AUTOSAR XML (schema 4-0-3)
standard types defined: Boolean, UInt16, UInt32
package /AUTOSAR_Platform/DataConstrs
  range DC_Boolean: raw 0..1
  range DC_UInt16: raw 0..65535
package /PATAC/MSM/ComponentTypes
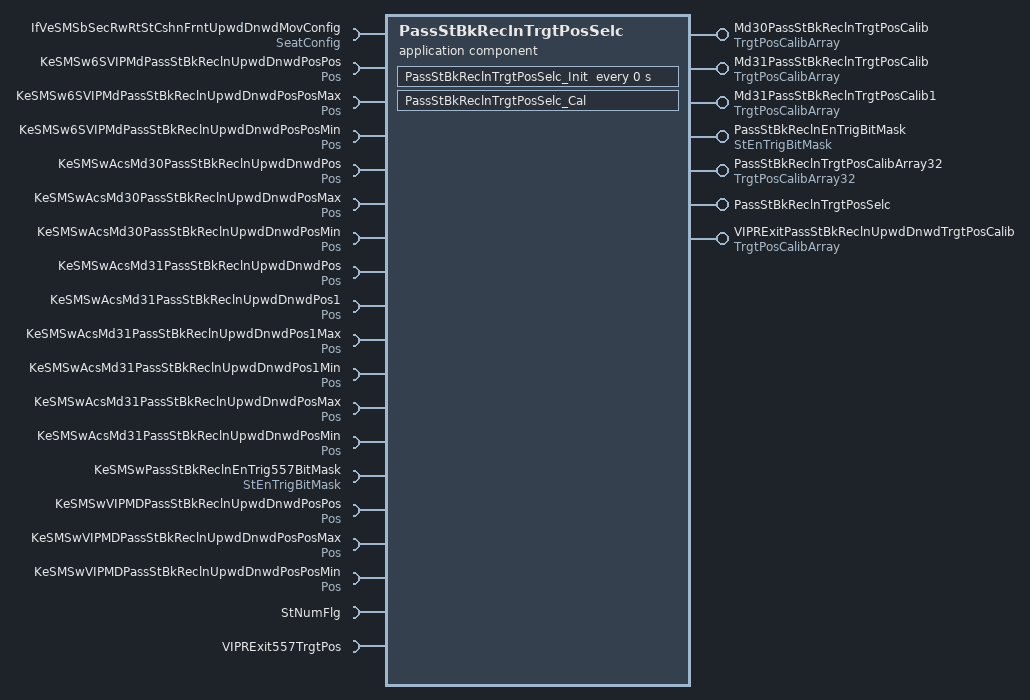
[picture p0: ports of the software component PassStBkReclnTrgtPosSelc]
  application sw component type PassStBkReclnTrgtPosSelc
    7 x provide port:
      Md30PassStBkReclnTrgtPosCalib: nonqueued-sender-com-spec{data-element=TrgtPosArray, init-value=[4095, 4095, 4095]}, provided-interface=TrgtPosCalibArray
      Md31PassStBkReclnTrgtPosCalib: nonqueued-sender-com-spec{data-element=TrgtPosArray, init-value=[4095, 4095, 4095]}, provided-interface=TrgtPosCalibArray
      Md31PassStBkReclnTrgtPosCalib1: nonqueued-sender-com-spec{data-element=TrgtPosArray, init-value=[4095, 4095, 4095]}, provided-interface=TrgtPosCalibArray
      PassStBkReclnEnTrigBitMask: nonqueued-sender-com-spec=data-element=StEnTrigBitMask/Val, provided-interface=StEnTrigBitMask
      PassStBkReclnTrgtPosCalibArray32: nonqueued-sender-com-spec{data-element=TrgtPosArray32, init-value=96 x 4095}, provided-interface=TrgtPosCalibArray32
      PassStBkReclnTrgtPosSelc: server-com-spec{operation=Cal, queue-length=1}, provided-interface=PassStBkReclnTrgtPosSelc
      VIPRExitPassStBkReclnUpwdDnwdTrgtPosCalib: nonqueued-sender-com-spec{data-element=TrgtPosArray, init-value=[4095, 4095, 4095]}, provided-interface=TrgtPosCalibArray
    19 x require port:
      IfVeSMSbSecRwRtStCshnFrntUpwdDnwdMovConfig: nonqueued-receiver-com-spec{data-element=SeatConfig/Val, filter=data-filter-type=ALWAYS, init-value=0}, required-interface=SeatConfig
      KeSMSw6SVIPMdPassStBkReclnUpwdDnwdPosPos: parameter-require-com-spec{init-value=0, parameter=Pos/Val}, required-interface=Pos
      KeSMSw6SVIPMdPassStBkReclnUpwdDnwdPosPosMax: parameter-require-com-spec{init-value=0, parameter=Pos/Val}, required-interface=Pos
      KeSMSw6SVIPMdPassStBkReclnUpwdDnwdPosPosMin: parameter-require-com-spec{init-value=0, parameter=Pos/Val}, required-interface=Pos
      KeSMSwAcsMd30PassStBkReclnUpwdDnwdPos: parameter-require-com-spec{init-value=0, parameter=Pos/Val}, required-interface=Pos
      KeSMSwAcsMd30PassStBkReclnUpwdDnwdPosMax: parameter-require-com-spec{init-value=0, parameter=Pos/Val}, required-interface=Pos
      KeSMSwAcsMd30PassStBkReclnUpwdDnwdPosMin: parameter-require-com-spec{init-value=0, parameter=Pos/Val}, required-interface=Pos
      KeSMSwAcsMd31PassStBkReclnUpwdDnwdPos: parameter-require-com-spec{init-value=0, parameter=Pos/Val}, required-interface=Pos
      KeSMSwAcsMd31PassStBkReclnUpwdDnwdPos1: parameter-require-com-spec{init-value=0, parameter=Pos/Val}, required-interface=Pos
      KeSMSwAcsMd31PassStBkReclnUpwdDnwdPos1Max: parameter-require-com-spec{init-value=0, parameter=Pos/Val}, required-interface=Pos
      KeSMSwAcsMd31PassStBkReclnUpwdDnwdPos1Min: parameter-require-com-spec{init-value=0, parameter=Pos/Val}, required-interface=Pos
      KeSMSwAcsMd31PassStBkReclnUpwdDnwdPosMax: parameter-require-com-spec{init-value=0, parameter=Pos/Val}, required-interface=Pos
      KeSMSwAcsMd31PassStBkReclnUpwdDnwdPosMin: parameter-require-com-spec{init-value=0, parameter=Pos/Val}, required-interface=Pos
      KeSMSwPassStBkReclnEnTrig557BitMask: parameter-require-com-spec{init-value=6153, parameter=StEnTrigBitMask/Val}, required-interface=StEnTrigBitMask
      KeSMSwVIPMDPassStBkReclnUpwdDnwdPosPos: parameter-require-com-spec{init-value=0, parameter=Pos/Val}, required-interface=Pos
      KeSMSwVIPMDPassStBkReclnUpwdDnwdPosPosMax: parameter-require-com-spec{init-value=0, parameter=Pos/Val}, required-interface=Pos
      KeSMSwVIPMDPassStBkReclnUpwdDnwdPosPosMin: parameter-require-com-spec{init-value=0, parameter=Pos/Val}, required-interface=Pos
      StNumFlg: required-interface=StNumFlg
        required-com-specs:
          data-element=Is4s, filter=data-filter-type=ALWAYS, init-value=0
          data-element=Is6s, filter=data-filter-type=ALWAYS, init-value=0
          data-element=Is6s7s, filter=data-filter-type=ALWAYS, init-value=0
          data-element=Is7s, filter=data-filter-type=ALWAYS, init-value=0
      VIPRExit557TrgtPos: required-com-specs=[Get, Set], required-interface=VIPRExit557TrgtPos
    behavior PassStBkReclnTrgtPosSelc_InternalBehavior
      operation invoked event OIT_PassStBkReclnTrgtPosSelc_Cal_PassStBkReclnTrgtPosSelc_Cal: start-on-event=PassStBkReclnTrgtPosSelc_Cal, operation=PassStBkReclnTrgtPosSelc.Cal
      timing event PassStBkReclnTrgtPosSelc_InitEvent: start-on-event=PassStBkReclnTrgtPosSelc_Init, period=0
      runnable PassStBkReclnTrgtPosSelc_Cal
        data-receive-point-by-arguments:
          5 x access:
            REC_IfVeSMSbSecRwRtStCshnFrntUpwdDnwdMovConfig_Val: accessed-variable=IfVeSMSbSecRwRtStCshnFrntUpwdDnwdMovConfig.Val
            REC_StNumFlg_Is4s: accessed-variable=StNumFlg.Is4s
            REC_StNumFlg_Is6s: accessed-variable=StNumFlg.Is6s
            REC_StNumFlg_Is6s7s: accessed-variable=StNumFlg.Is6s7s
            REC_StNumFlg_Is7s: accessed-variable=StNumFlg.Is7s
        data-send-points:
          6 x access:
            SEND_Md30PassStBkReclnTrgtPosCalib_TrgtPosArray: accessed-variable=Md30PassStBkReclnTrgtPosCalib.TrgtPosArray
            SEND_Md31PassStBkReclnTrgtPosCalib_TrgtPosArray: accessed-variable=Md31PassStBkReclnTrgtPosCalib.TrgtPosArray
            SEND_Md31PassStBkReclnTrgtPosCalib1_TrgtPosArray: accessed-variable=Md31PassStBkReclnTrgtPosCalib1.TrgtPosArray
            SEND_PassStBkReclnEnTrigBitMask_Val: accessed-variable=PassStBkReclnEnTrigBitMask.Val
            SEND_PassStBkReclnTrgtPosCalibArray32_TrgtPosArray32: accessed-variable=PassStBkReclnTrgtPosCalibArray32.TrgtPosArray32
            SEND_VIPRExitPassStBkReclnUpwdDnwdTrgtPosCalib_TrgtPosArray: accessed-variable=VIPRExitPassStBkReclnUpwdDnwdTrgtPosCalib.TrgtPosArray
        16 x parameter access:
          PA_KeSMSw6SVIPMdPassStBkReclnUpwdDnwdPosPos_Val: accessed-parameter=KeSMSw6SVIPMdPassStBkReclnUpwdDnwdPosPos.Val
          PA_KeSMSw6SVIPMdPassStBkReclnUpwdDnwdPosPosMax_Val: accessed-parameter=KeSMSw6SVIPMdPassStBkReclnUpwdDnwdPosPosMax.Val
          PA_KeSMSw6SVIPMdPassStBkReclnUpwdDnwdPosPosMin_Val: accessed-parameter=KeSMSw6SVIPMdPassStBkReclnUpwdDnwdPosPosMin.Val
          PA_KeSMSwAcsMd30PassStBkReclnUpwdDnwdPos_Val: accessed-parameter=KeSMSwAcsMd30PassStBkReclnUpwdDnwdPos.Val
          PA_KeSMSwAcsMd30PassStBkReclnUpwdDnwdPosMax_Val: accessed-parameter=KeSMSwAcsMd30PassStBkReclnUpwdDnwdPosMax.Val
          PA_KeSMSwAcsMd30PassStBkReclnUpwdDnwdPosMin_Val: accessed-parameter=KeSMSwAcsMd30PassStBkReclnUpwdDnwdPosMin.Val
          PA_KeSMSwAcsMd31PassStBkReclnUpwdDnwdPos_Val: accessed-parameter=KeSMSwAcsMd31PassStBkReclnUpwdDnwdPos.Val
          PA_KeSMSwAcsMd31PassStBkReclnUpwdDnwdPos1_Val: accessed-parameter=KeSMSwAcsMd31PassStBkReclnUpwdDnwdPos1.Val
          PA_KeSMSwAcsMd31PassStBkReclnUpwdDnwdPos1Max_Val: accessed-parameter=KeSMSwAcsMd31PassStBkReclnUpwdDnwdPos1Max.Val
          PA_KeSMSwAcsMd31PassStBkReclnUpwdDnwdPos1Min_Val: accessed-parameter=KeSMSwAcsMd31PassStBkReclnUpwdDnwdPos1Min.Val
          PA_KeSMSwAcsMd31PassStBkReclnUpwdDnwdPosMax_Val: accessed-parameter=KeSMSwAcsMd31PassStBkReclnUpwdDnwdPosMax.Val
          PA_KeSMSwAcsMd31PassStBkReclnUpwdDnwdPosMin_Val: accessed-parameter=KeSMSwAcsMd31PassStBkReclnUpwdDnwdPosMin.Val
          PA_KeSMSwPassStBkReclnEnTrig557BitMask_Val: accessed-parameter=KeSMSwPassStBkReclnEnTrig557BitMask.Val
          PA_KeSMSwVIPMDPassStBkReclnUpwdDnwdPosPos_Val: accessed-parameter=KeSMSwVIPMDPassStBkReclnUpwdDnwdPosPos.Val
          PA_KeSMSwVIPMDPassStBkReclnUpwdDnwdPosPosMax_Val: accessed-parameter=KeSMSwVIPMDPassStBkReclnUpwdDnwdPosPosMax.Val
          PA_KeSMSwVIPMDPassStBkReclnUpwdDnwdPosPosMin_Val: accessed-parameter=KeSMSwVIPMDPassStBkReclnUpwdDnwdPosPosMin.Val
        sync call SC_VIPRExit557TrgtPos_Get: operation=VIPRExit557TrgtPos.Get, timeout=0
      runnable PassStBkReclnTrgtPosSelc_Init
        16 x parameter access:
          PA_KeSMSw6SVIPMdPassStBkReclnUpwdDnwdPosPos_Val: accessed-parameter=KeSMSw6SVIPMdPassStBkReclnUpwdDnwdPosPos.Val
          PA_KeSMSw6SVIPMdPassStBkReclnUpwdDnwdPosPosMax_Val: accessed-parameter=KeSMSw6SVIPMdPassStBkReclnUpwdDnwdPosPosMax.Val
          PA_KeSMSw6SVIPMdPassStBkReclnUpwdDnwdPosPosMin_Val: accessed-parameter=KeSMSw6SVIPMdPassStBkReclnUpwdDnwdPosPosMin.Val
          PA_KeSMSwAcsMd30PassStBkReclnUpwdDnwdPos_Val: accessed-parameter=KeSMSwAcsMd30PassStBkReclnUpwdDnwdPos.Val
          PA_KeSMSwAcsMd30PassStBkReclnUpwdDnwdPosMax_Val: accessed-parameter=KeSMSwAcsMd30PassStBkReclnUpwdDnwdPosMax.Val
          PA_KeSMSwAcsMd30PassStBkReclnUpwdDnwdPosMin_Val: accessed-parameter=KeSMSwAcsMd30PassStBkReclnUpwdDnwdPosMin.Val
          PA_KeSMSwAcsMd31PassStBkReclnUpwdDnwdPos_Val: accessed-parameter=KeSMSwAcsMd31PassStBkReclnUpwdDnwdPos.Val
          PA_KeSMSwAcsMd31PassStBkReclnUpwdDnwdPos1_Val: accessed-parameter=KeSMSwAcsMd31PassStBkReclnUpwdDnwdPos1.Val
          PA_KeSMSwAcsMd31PassStBkReclnUpwdDnwdPos1Max_Val: accessed-parameter=KeSMSwAcsMd31PassStBkReclnUpwdDnwdPos1Max.Val
          PA_KeSMSwAcsMd31PassStBkReclnUpwdDnwdPos1Min_Val: accessed-parameter=KeSMSwAcsMd31PassStBkReclnUpwdDnwdPos1Min.Val
          PA_KeSMSwAcsMd31PassStBkReclnUpwdDnwdPosMax_Val: accessed-parameter=KeSMSwAcsMd31PassStBkReclnUpwdDnwdPosMax.Val
          PA_KeSMSwAcsMd31PassStBkReclnUpwdDnwdPosMin_Val: accessed-parameter=KeSMSwAcsMd31PassStBkReclnUpwdDnwdPosMin.Val
          PA_KeSMSwPassStBkReclnEnTrig557BitMask_Val: accessed-parameter=KeSMSwPassStBkReclnEnTrig557BitMask.Val
          PA_KeSMSwVIPMDPassStBkReclnUpwdDnwdPosPos_Val: accessed-parameter=KeSMSwVIPMDPassStBkReclnUpwdDnwdPosPos.Val
          PA_KeSMSwVIPMDPassStBkReclnUpwdDnwdPosPosMax_Val: accessed-parameter=KeSMSwVIPMDPassStBkReclnUpwdDnwdPosPosMax.Val
          PA_KeSMSwVIPMDPassStBkReclnUpwdDnwdPosPosMin_Val: accessed-parameter=KeSMSwVIPMDPassStBkReclnUpwdDnwdPosPosMin.Val
  swc implementation PassStBkReclnTrgtPosSelc_Implementation: behavior=PassStBkReclnTrgtPosSelc_InternalBehavior
    code-descriptors:
      code Default: artifact-descriptors=autosar-engineering-object={short-label=Default, category=SWSRC}
package /PATAC/MSM/ModeAdjust/CalPortInterface
  parameter interface Pos
    parameter data prototype Val: sw-calibration-access=READ-WRITE, type=UInt16
  parameter interface StEnTrigBitMask
    parameter data prototype Val: sw-calibration-access=READ-WRITE, type=UInt32
package /PATAC/MSM/ModeAdjust/DataType
  impl type TrgtPosCalibArray: category=ARRAY, sw-calibration-access=READ-ONLY, type-emitter=RTE  # 0:pos 1:max 2:min
    element Element: array-size=3, array-size-semantics=FIXED-SIZE, implementation-data-type=UInt16, invalid-value=0
  impl type TrgtPosCalibArray32: category=ARRAY, sw-calibration-access=READ-ONLY, type-emitter=RTE  # 0:pos 1:max 2:min
    element Element: array-size=96, array-size-semantics=FIXED-SIZE, implementation-data-type=UInt16, invalid-value=0
package /PATAC/MSM/ModeAdjust/PortInterface
  client server interface PassStBkReclnTrgtPosSelc
    operation Cal
  client server interface VIPRExit557TrgtPos
    operation Get
      11 x arg, all with type=UInt16, direction=OUT, server-argument-impl-policy=USE-ARGUMENT-TYPE:
        SecRwRtStBkReclnTrgtPos
        SecRwRtStZeroTrgtPos
        SecRwRtStLgrstUpwdDnwdTrgtPos
        SecRwRtStLgrstInwdOtwdTrgtPos
        ThdRwLtStBkReclnTrgtPos
        ThdRwLtStFwdBkwdTrgtPos
        ThdRwRtStBkReclnTrgtPos
        ThdRwRtStFwdBkwdTrgtPos
        PassStBkReclnTrgtPos
        PassStFwdBkwdTrgtPos
        SecRwRtStFwdBkwdTrgtPos
    operation Set
      11 x arg, all with type=UInt16, direction=IN, server-argument-impl-policy=USE-ARGUMENT-TYPE:
        SecRwRtStBkReclnTrgtPos
        SecRwRtStZeroTrgtPos
        SecRwRtStLgrstUpwdDnwdTrgtPos
        SecRwRtStLgrstInwdOtwdTrgtPos
        ThdRwLtStBkReclnTrgtPos
        ThdRwLtStFwdBkwdTrgtPos
        ThdRwRtStBkReclnTrgtPos
        ThdRwRtStFwdBkwdTrgtPos
        PassStBkReclnTrgtPos
        PassStFwdBkwdTrgtPos
        SecRwRtStFwdBkwdTrgtPos
  4 x sender receiver interface:
    StEnTrigBitMask: invalidation-policy{data-element=StEnTrigBitMask/Val, handle-invalid=DONT-INVALIDATE}
      data Val: type=UInt32
    StNumFlg
      4 x data, all with type=Boolean:
        Is4s
        Is6s
        Is6s7s
        Is7s
      invalidation-policys:
        data-element=Is4s, handle-invalid=DONT-INVALIDATE
        data-element=Is6s, handle-invalid=DONT-INVALIDATE
        data-element=Is6s7s, handle-invalid=DONT-INVALIDATE
        data-element=Is7s, handle-invalid=DONT-INVALIDATE
    TrgtPosCalibArray: invalidation-policy{data-element=TrgtPosArray, handle-invalid=DONT-INVALIDATE}
      data TrgtPosArray: type=TrgtPosCalibArray  # 0:Pos 1:Max 2:Min
    TrgtPosCalibArray32: invalidation-policy{data-element=TrgtPosArray32, handle-invalid=DONT-INVALIDATE}
      data TrgtPosArray32: type=TrgtPosCalibArray32  # 0:Pos 1:Max 2:Min
package /PATAC/MSM/PortInterfaces
  sender receiver interface SeatConfig: invalidation-policy{data-element=SeatConfig/Val, handle-invalid=DONT-INVALIDATE}
    data Val: type=Boolean
